# VPAC0_COMMON_0_PAR_VPAC_VISS0_S_VBUSP_VISS_NSF4V_CFG_MMR_VBUSP_NSF4VCORE register map
Vendor: Texas Instruments
Peripheral module from a debugger description file (folder J721S2).
Registers are 32-bit, read-write, reset values left out (the file's numbers can be read two ways) unless marked. A register's access mark holds for its fields unless they carry their own. Offsets are as the file gives them; lines under a group give offsets from that group; [hi:lo] are bit positions; {n}, {i} and the like mark numbered series; 'fields as' and 'values as' point back to an identical list; <NAME> marks a mode.

## VPAC0_COMMON_0_PAR_VPAC_VISS0_S_VBUSP_VISS_NSF4V_CFG_MMR_VBUSP_NSF4VCORE
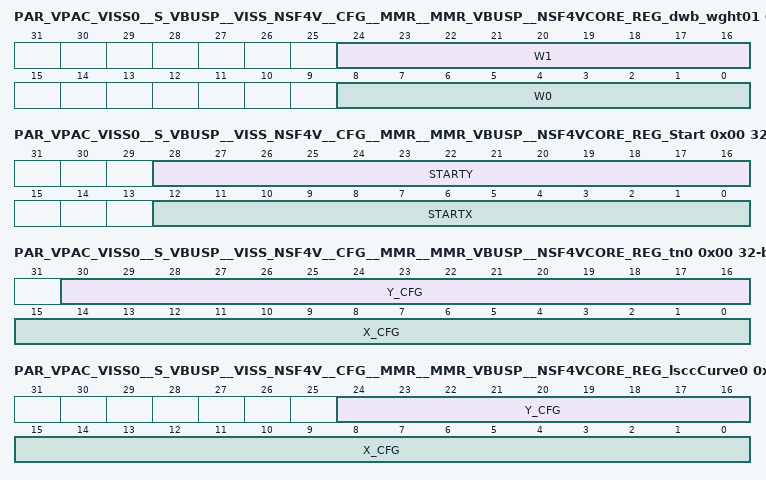
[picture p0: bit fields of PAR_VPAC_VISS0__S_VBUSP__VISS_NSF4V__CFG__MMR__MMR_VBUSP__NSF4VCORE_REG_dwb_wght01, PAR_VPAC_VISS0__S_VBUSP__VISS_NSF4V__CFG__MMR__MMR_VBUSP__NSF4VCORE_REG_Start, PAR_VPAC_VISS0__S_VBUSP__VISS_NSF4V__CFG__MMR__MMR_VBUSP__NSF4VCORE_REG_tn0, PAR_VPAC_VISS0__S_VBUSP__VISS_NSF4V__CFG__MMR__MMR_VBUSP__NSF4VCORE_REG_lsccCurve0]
0x00 PAR_VPAC_VISS0__S_VBUSP__VISS_NSF4V__CFG__MMR__MMR_VBUSP__NSF4VCORE_REG_dwb_wght01
  [24:16] W1 — U9Q8 Weight1
  [8:0] W0 — U9Q8 Weight0
0x00 PAR_VPAC_VISS0__S_VBUSP__VISS_NSF4V__CFG__MMR__MMR_VBUSP__NSF4VCORE_REG_Start
  [28:16] STARTY — Valid line start Vertically. Needs to be even. Minimum is 2 and should be greater than previous region EndY
  [12:0] STARTX — Valid pixel start Horizontally. Has to be even
0x00 PAR_VPAC_VISS0__S_VBUSP__VISS_NSF4V__CFG__MMR__MMR_VBUSP__NSF4VCORE_REG_tn0
  [30:16] Y_CFG — (U15) Y (U) value. T_n resulting value from lookup. Starting point from which SLOPE will linearly calculate between X Y points
  [15:0] X_CFG — (U16) X (LL2) value. LL2 averaged input value into lookup rounded down to nearest X value. (X0 programmed value is unused and defaults to a value of 0 in hardware implementation)
0x00 PAR_VPAC_VISS0__S_VBUSP__VISS_NSF4V__CFG__MMR__MMR_VBUSP__NSF4VCORE_REG_lsccCurve0
  [24:16] Y_CFG — (U15.0) Y (U) value. LSCC Gain resulting value from lookup. Starting point from which SLOPE will linearly calculate between X Y points
  [15:0] X_CFG — (U16) X (normalized radius from center) value. Input rounded down to nearest X value. (X0 programmed value is unused and defaults to a value of 0 in hardware implementation)
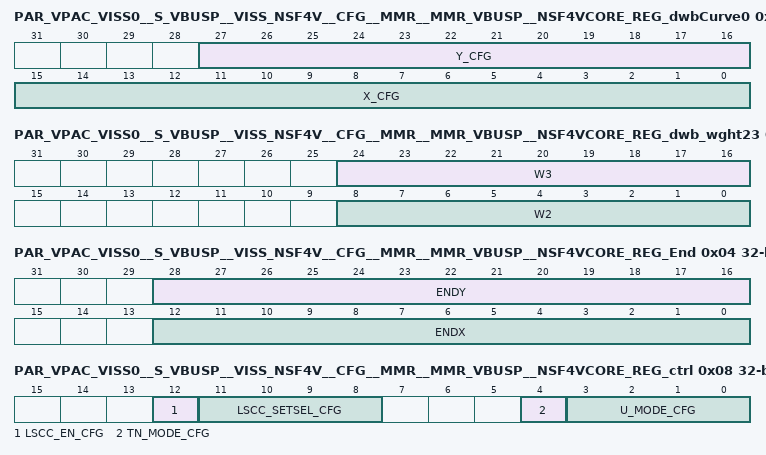
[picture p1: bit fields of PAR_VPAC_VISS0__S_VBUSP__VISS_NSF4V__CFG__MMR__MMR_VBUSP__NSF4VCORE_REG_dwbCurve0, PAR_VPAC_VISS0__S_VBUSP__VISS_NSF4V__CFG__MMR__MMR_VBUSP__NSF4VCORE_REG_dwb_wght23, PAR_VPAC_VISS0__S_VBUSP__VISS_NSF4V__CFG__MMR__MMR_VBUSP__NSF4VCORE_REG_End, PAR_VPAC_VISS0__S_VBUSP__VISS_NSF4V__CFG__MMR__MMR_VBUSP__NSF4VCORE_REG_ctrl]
0x00 PAR_VPAC_VISS0__S_VBUSP__VISS_NSF4V__CFG__MMR__MMR_VBUSP__NSF4VCORE_REG_dwbCurve0
  [27:16] Y_CFG — U12Q8 Y Reference value from the segment. Starting point from which SLOPE will linearly calculate between X Y points
  [15:0] X_CFG — U16 X Intesity value. X0 programmed value is unused and defaults to a value of 0 in hardware implementation
0x04 PAR_VPAC_VISS0__S_VBUSP__VISS_NSF4V__CFG__MMR__MMR_VBUSP__NSF4VCORE_REG_dbg
  [5:0] RAM_MUX_CFG — Diagnostic Rd Wr access to Embedded RAM Selector Mux. This bit controls the mux select or which RAM and which section of that RAM are assessed via the VBUSP read of RAM. (This MMR is not shadowed)
0x04 PAR_VPAC_VISS0__S_VBUSP__VISS_NSF4V__CFG__MMR__MMR_VBUSP__NSF4VCORE_REG_dwb_wght23
  [24:16] W3 — U9Q8 Weight3
  [8:0] W2 — U9Q8 Weight2
0x04 PAR_VPAC_VISS0__S_VBUSP__VISS_NSF4V__CFG__MMR__MMR_VBUSP__NSF4VCORE_REG_End
  [28:16] ENDY — Valid line end Vertically. Min region height is 8 and region height has to be even
  [12:0] ENDX — Valid pixel end Horizontally. Min region width is 8 and region width has to be even
0x04 PAR_VPAC_VISS0__S_VBUSP__VISS_NSF4V__CFG__MMR__MMR_VBUSP__NSF4VCORE_REG_tn1
  [15:0] S_CFG — (S5.11) S value. Slope value used calculated linear interpolation between X Y points
0x04 PAR_VPAC_VISS0__S_VBUSP__VISS_NSF4V__CFG__MMR__MMR_VBUSP__NSF4VCORE_REG_lsccCurve1
  fields as PAR_VPAC_VISS0__S_VBUSP__VISS_NSF4V__CFG__MMR__MMR_VBUSP__NSF4VCORE_REG_tn1
0x04 PAR_VPAC_VISS0__S_VBUSP__VISS_NSF4V__CFG__MMR__MMR_VBUSP__NSF4VCORE_REG_dwbCurve1
  [15:0] S_CFG — S16Q12 Slope value for the segment. Slope value used calculated linear interpolation between X Y points
0x08 PAR_VPAC_VISS0__S_VBUSP__VISS_NSF4V__CFG__MMR__MMR_VBUSP__NSF4VCORE_REG_ctrl
  [12] LSCC_EN_CFG — enable Lens Shading Correction Compensation. When disabled, implments a unity gain
  [11:8] LSCC_SETSEL_CFG — bit per BAYER color component indicating which of two sets of 16 segment PWL Curve to use for LSCC. 0: use set0 1: use set1
  [4] TN_MODE_CFG — single bit controlling T_n calculation 0: use u_mode bits to indicate which LL2 to average and which bits to keep independent without averaging 1: independent no averaging
  [3:0] U_MODE_CFG — bit per BAYER color component indicating Decomp sub component 0: average with others 1: independent color component do not average for calculation of U Suppress. bit[0]:color 0 at (v=0, h=0) bit[1]:color 1 at (v=0, h=1) bit[2]:color 2 at (v=1, h=0) bit[3]:color 3 at (v=1, h=1)
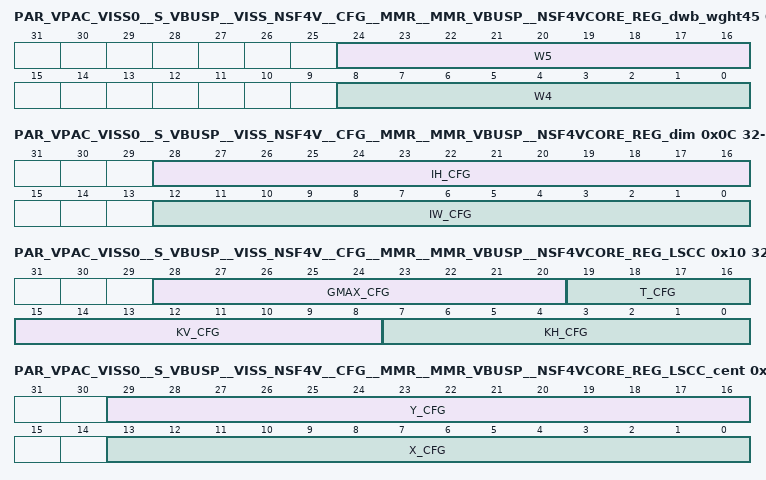
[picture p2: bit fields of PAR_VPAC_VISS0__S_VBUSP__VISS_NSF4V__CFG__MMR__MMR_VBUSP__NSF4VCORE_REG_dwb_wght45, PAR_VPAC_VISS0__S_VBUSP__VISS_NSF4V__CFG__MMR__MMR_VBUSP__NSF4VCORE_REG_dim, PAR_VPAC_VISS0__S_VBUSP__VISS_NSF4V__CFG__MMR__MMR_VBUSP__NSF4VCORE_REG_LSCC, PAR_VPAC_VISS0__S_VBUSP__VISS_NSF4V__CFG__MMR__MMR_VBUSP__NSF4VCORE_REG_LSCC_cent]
0x08 PAR_VPAC_VISS0__S_VBUSP__VISS_NSF4V__CFG__MMR__MMR_VBUSP__NSF4VCORE_REG_dwb_wght45
  [24:16] W5 — U9Q8 Weight5
  [8:0] W4 — U9Q8 Weight4
0x0C PAR_VPAC_VISS0__S_VBUSP__VISS_NSF4V__CFG__MMR__MMR_VBUSP__NSF4VCORE_REG_dim
  [28:16] IH_CFG — (U13) input height in units of pixels minus 1.
  [12:0] IW_CFG — (U13) input width in units of pixels minus 1. Max usable value determined by populated line buffer RAM size
0x10 PAR_VPAC_VISS0__S_VBUSP__VISS_NSF4V__CFG__MMR__MMR_VBUSP__NSF4VCORE_REG_LSCC
  [28:20] GMAX_CFG — (U4.5) LSCC maximum gain. Any calculated value is clipped to this max value
  [19:16] T_CFG — (U4) LSCC radius dynamic range select. T is the right shift amount prior to MSB clip.
  [15:8] KV_CFG — (U2.6) LSCC horizontal or Y Gain for elliptical lens
  [7:0] KH_CFG — (U2.6) LSCC vertical or X Gain for elliptical lens
0x14 PAR_VPAC_VISS0__S_VBUSP__VISS_NSF4V__CFG__MMR__MMR_VBUSP__NSF4VCORE_REG_LSCC_cent
  [29:16] Y_CFG — (S14) Vertical (Y) position of lens center. Negative value supports the case where processed frame starts after the center. HW supports center config with below constraint. if (Y_cfg < 0) # negative DIM.ih_cfg + abs(Y_cfg) < 8K else # positive Y_cfg < 8K
  [13:0] X_CFG — (S14) Horizontal (X) position of lens center. Negative value supports the case where processed frame starts after the center. HW supports center config with below constraint. if (X_cfg < 0) # negative DIM.iw_cfg + abs(X_cfg) < 8K else # positive X_cfg < 8K
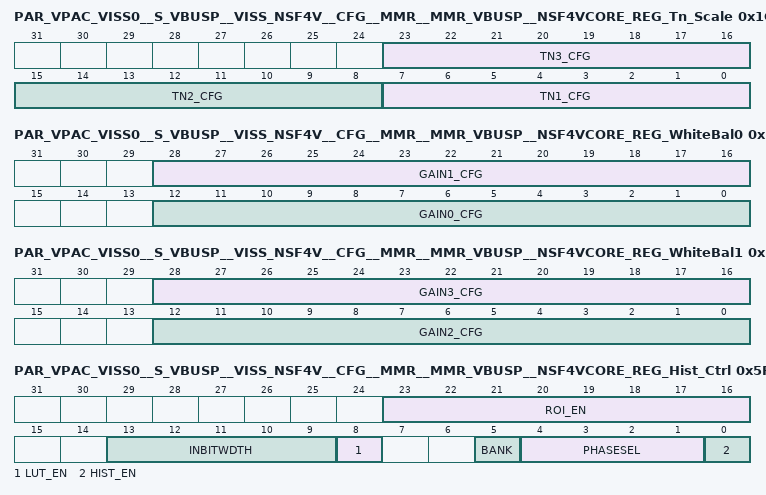
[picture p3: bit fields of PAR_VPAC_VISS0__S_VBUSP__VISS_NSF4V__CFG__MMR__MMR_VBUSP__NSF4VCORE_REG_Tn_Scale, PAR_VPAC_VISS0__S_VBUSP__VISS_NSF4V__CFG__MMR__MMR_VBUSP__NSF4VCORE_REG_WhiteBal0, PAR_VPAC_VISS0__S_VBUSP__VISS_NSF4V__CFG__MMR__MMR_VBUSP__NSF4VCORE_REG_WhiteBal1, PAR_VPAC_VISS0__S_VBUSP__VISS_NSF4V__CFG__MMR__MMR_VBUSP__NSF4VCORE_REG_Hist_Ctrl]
0x1C PAR_VPAC_VISS0__S_VBUSP__VISS_NSF4V__CFG__MMR__MMR_VBUSP__NSF4VCORE_REG_Tn_Scale
  [23:16] TN3_CFG — (U3.5) Level3. Sub-bands 7, 8, 9
  [15:8] TN2_CFG — (U3.5) Level2. Sub-bands 4, 5, 6
  [7:0] TN1_CFG — (U3.5) Level1. Sub-bands 0, 1, 2
0x20 PAR_VPAC_VISS0__S_VBUSP__VISS_NSF4V__CFG__MMR__MMR_VBUSP__NSF4VCORE_REG_U_knee
  [5:0] U_KNEE_CFG — (U0.6) U Suppress curve knee. X (LL2) value which separates constant suppression of 1.0 from linear suppression.
0x24 PAR_VPAC_VISS0__S_VBUSP__VISS_NSF4V__CFG__MMR__MMR_VBUSP__NSF4VCORE_REG_WhiteBal0
  [28:16] GAIN1_CFG — (U4.9) Gain for color 1
  [12:0] GAIN0_CFG — (U4.9) Gain for color 0
0x28 PAR_VPAC_VISS0__S_VBUSP__VISS_NSF4V__CFG__MMR__MMR_VBUSP__NSF4VCORE_REG_WhiteBal1
  [28:16] GAIN3_CFG — (U4.9) Gain for color 3
  [12:0] GAIN2_CFG — (U4.9) Gain for color 2
0x3F0 PAR_VPAC_VISS0__S_VBUSP__VISS_NSF4V__CFG__MMR__MMR_VBUSP__NSF4VCORE_REG_DWB_CNTL
  [0] DWB_EN — Dynamic White Balance Enable
0x5F0 PAR_VPAC_VISS0__S_VBUSP__VISS_NSF4V__CFG__MMR__MMR_VBUSP__NSF4VCORE_REG_Hist_Ctrl
  [23:16] ROI_EN — Enable for ROIs. Each bit corresponds to one ROI. bit[x] to ROI[x]. Use lower index regions if less than 8 regions are needed.
  [13:9] INBITWDTH — BitWidth of the input image, values greater than 16 will be treated as 16 and values less than 12 will be treated as 12
  [8] LUT_EN — 0->Use shift(bitwidth-12), 1->Use LUT
  [5] BANK — Bank attached to Histogram HW Datapath. Shadowed and internal control is updated outisde of active frame 0 -> HW access Bank0 & Cfg MMR access Bank1 1 -> HW access Bank1 & Cfg MMR access Bank0.
  [4:1] PHASESEL — Histogram Phase select enable; one bit for each color channel. Up to 2 bits can be enabled; only bit can be enabled per line. bit[0]:color 0 at (v=0, h=0) bit[1]:color 1 at (v=0, h=1) bit[2]:color 2 at (v=1, h=0) bit[3]:color 3 at (v=1, h=1)
  [0] HIST_EN — Raw domain Histogram Enable. When enbaled minimum frame width has to be 128
